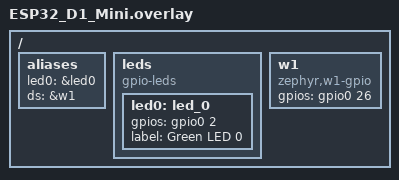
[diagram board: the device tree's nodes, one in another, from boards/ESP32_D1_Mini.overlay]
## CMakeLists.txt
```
# SPDX-License-Identifier: Apache-2.0

cmake_minimum_required(VERSION 3.20.0)

find_package(Zephyr REQUIRED HINTS $ENV{ZEPHYR_BASE})
project(ds18b20)

target_sources(app PRIVATE src/main.c
                            src/ds18b20.c)
```

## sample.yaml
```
sample:
  description: Test for DS18B20 temperature sensor
    application
  name: ds18b20
common:
  min_ram: 2
  min_flash: 16
  tags: introduction
  integration_platforms:
    - native_sim
  harness: console
  harness_config:
    type: one_line
    regex:
      - "ds18b20! (.*)"
tests:
  sample.basic.ds18b20:
    tags: introduction
```

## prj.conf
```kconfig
CONFIG_CBPRINTF_FP_SUPPORT=y
CONFIG_W1=y
```

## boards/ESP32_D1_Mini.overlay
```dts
/* SPDX-License-Identifier: Apache-2.0 */

/ {
	aliases {
		led0 = &led0;
		ds = &w1;
	};

	leds {
		compatible = "gpio-leds";
		led0: led_0 {
			gpios = <&gpio0 2 GPIO_ACTIVE_HIGH>;
			label = "Green LED 0";
		};
	};
	    

    w1: w1 {
            compatible = "zephyr,w1-gpio";
            gpios = <&gpio0 26 (GPIO_ACTIVE_HIGH | GPIO_OPEN_DRAIN)>;
			status = "okay";
    };

};
```

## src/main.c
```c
/*
 */
#include <zephyr/kernel.h>
#include <zephyr/drivers/gpio.h>
#include <zephyr/device.h>
#include <zephyr/devicetree.h>
#include "ds18b20.h"


#include <stdio.h>

int main(void)
{
	float temp = 15.78;

	printk("TP: %f\n", (double)temp);
	ds18b20_setResolution(12);
	temp = ds18b20_get_temp_method_2();

	printk("Temperature: %f \n", (double)temp);

	while (1)
	{
		k_sleep(K_SECONDS(2));
		temp = ds18b20_get_temp_method_2();
		printk("Temperature: %f \n", (double)temp);
	}

	return 0;
}
```

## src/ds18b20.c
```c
/*
  */

#include <zephyr/kernel.h>
#include <zephyr/drivers/gpio.h>
#include <zephyr/device.h>
#include <zephyr/devicetree.h>
#include <zephyr/drivers/w1.h>
#include "ds18b20.h"

// Commands
#define STARTCONVO 0x44
#define READSCRATCH 0xBE
#define WRITESCRATCH 0x4E

// Scratchpad locations
#define TEMP_LSB 0
#define TEMP_MSB 1

// Device resolution
#define TEMP_9_BIT 0x1F  //  9 bit
#define TEMP_10_BIT 0x3F // 10 bit
#define TEMP_11_BIT 0x5F // 11 bit
#define TEMP_12_BIT 0x7F // 12 bit

typedef uint8_t ScratchPad[9];

#define DS_PIN DT_ALIAS(ds)
const struct device *const dev = DEVICE_DT_GET(DS_PIN);

int ds18b20_init(void)
{
 	if (!device_is_ready(dev))
	{
		return 0;
	}
    return 1;
}

/**@brief Function for reading scratchpad value
 */
void ds18b20_readScratchPad(uint8_t *scratchPad, uint8_t fields)
{
    w1_reset_bus(dev);
    w1_write_byte(dev, 0xCC);
    w1_write_byte(dev, READSCRATCH);

    for (uint8_t i = 0; i < fields; i++)
    {
        scratchPad[i] = w1_read_byte(dev);
    }
    w1_reset_bus(dev);
}

/**@brief Function for reading temperature.
 */
float ds18b20_get_temp(void)
{
    int check;
    char temp1 = 0, temp2 = 0;
    float temp;

    check = w1_reset_bus(dev);
    if (check)
    {
 		w1_write_byte(dev, 0xCC);
		w1_write_byte(dev, 0x44);
		while (w1_read_bit(dev) == 0);
		w1_reset_bus(dev);
		w1_write_byte(dev, 0xCC);
		w1_write_byte(dev, 0xBE);
		temp1 = w1_read_byte(dev);
		temp2 = w1_read_byte(dev);
		w1_reset_bus(dev);
		temp = (float)(temp1 + (temp2 * 256)) / 16;
        return temp;
    }
    return 0;
}

/**@brief Function for request temperature reading
 */
void ds18b20_requestTemperatures(void)
{
    w1_reset_bus(dev);
    w1_write_byte(dev, 0xCC);
    w1_write_byte(dev, STARTCONVO);
}



/**@brief Function for reading temperature method 2
 */
float ds18b20_get_temp_method_2(void)
{
    ScratchPad scratchPad;

    ds18b20_requestTemperatures();
    ds18b20_readScratchPad(scratchPad, 2);
    int16_t rawTemperature = (((int16_t)scratchPad[TEMP_MSB]) << 8) | scratchPad[TEMP_LSB];
    float temp = 0.0625 * rawTemperature;
    return temp;
}

/**@brief Function for setting temperature resolution
 */
void ds18b20_setResolution(int resolution)
{
    w1_reset_bus(dev);
    w1_write_byte(dev, 0xCC);
    w1_write_byte(dev, WRITESCRATCH);
    // two dummy values for LOW & HIGH ALARM
    w1_write_byte(dev, 0x00);
    w1_write_byte(dev, 100);
    switch (resolution)
    {
    case 12:
        w1_write_byte(dev, TEMP_12_BIT);
        break;

    case 11:
        w1_write_byte(dev, TEMP_11_BIT);
        break;

    case 10:
        w1_write_byte(dev, TEMP_10_BIT);
        break;

    case 9:
    default:
        w1_write_byte(dev, TEMP_9_BIT);
        break;
    }
    w1_reset_bus(dev);
}
```

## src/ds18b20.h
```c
/**
 * Copyright (c) 2015 - 2018, Nordic Semiconductor ASA
 * 
 * All rights reserved.
 * 
 * Redistribution and use in source and binary forms, with or without modification,
 * are permitted provided that the following conditions are met:
 * 
 * 1. Redistributions of source code must retain the above copyright notice, this
 *    list of conditions and the following disclaimer.
 * 
 * 2. Redistributions in binary form, except as embedded into a Nordic
 *    Semiconductor ASA integrated circuit in a product or a software update for
 *    such product, must reproduce the above copyright notice, this list of
 *    conditions and the following disclaimer in the documentation and/or other
 *    materials provided with the distribution.
 * 
 * 3. Neither the name of Nordic Semiconductor ASA nor the names of its
 *    contributors may be used to endorse or promote products derived from this
 *    software without specific prior written permission.
 * 
 * 4. This software, with or without modification, must only be used with a
 *    Nordic Semiconductor ASA integrated circuit.
 * 
 * 5. Any software provided in binary form under this license must not be reverse
 *    engineered, decompiled, modified and/or disassembled.
 * 
 * THIS SOFTWARE IS PROVIDED BY NORDIC SEMICONDUCTOR ASA "AS IS" AND ANY EXPRESS
 * OR IMPLIED WARRANTIES, INCLUDING, BUT NOT LIMITED TO, THE IMPLIED WARRANTIES
 * OF MERCHANTABILITY, NONINFRINGEMENT, AND FITNESS FOR A PARTICULAR PURPOSE ARE
 * DISCLAIMED. IN NO EVENT SHALL NORDIC SEMICONDUCTOR ASA OR CONTRIBUTORS BE
 * LIABLE FOR ANY DIRECT, INDIRECT, INCIDENTAL, SPECIAL, EXEMPLARY, OR
 * CONSEQUENTIAL DAMAGES (INCLUDING, BUT NOT LIMITED TO, PROCUREMENT OF SUBSTITUTE
 * GOODS OR SERVICES; LOSS OF USE, DATA, OR PROFITS; OR BUSINESS INTERRUPTION)
 * HOWEVER CAUSED AND ON ANY THEORY OF LIABILITY, WHETHER IN CONTRACT, STRICT
 * LIABILITY, OR TORT (INCLUDING NEGLIGENCE OR OTHERWISE) ARISING IN ANY WAY OUT
 * OF THE USE OF THIS SOFTWARE, EVEN IF ADVISED OF THE POSSIBILITY OF SUCH DAMAGE.
 * 
 */

 
int ds18b20_init(void);
float ds18b20_get_temp(void);
void ds18b20_setResolution(int resolution);
float ds18b20_get_temp_method_2(void);
/** @} */
```
